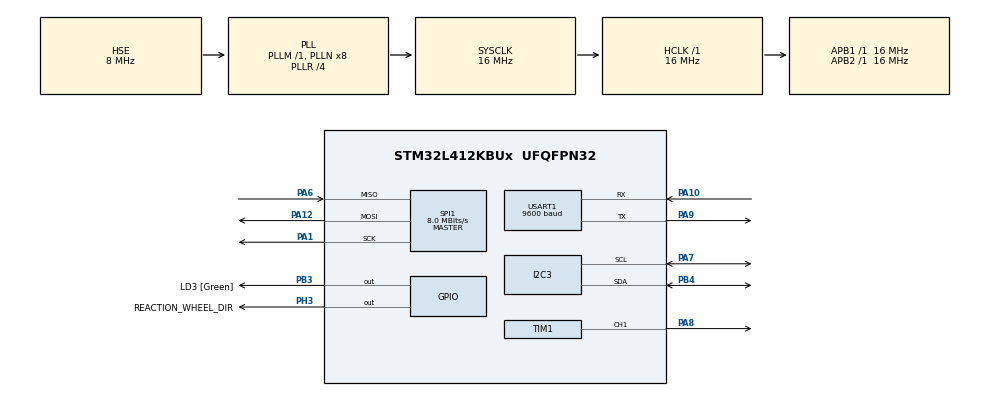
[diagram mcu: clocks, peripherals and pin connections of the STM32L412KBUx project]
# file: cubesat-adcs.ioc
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FREERTOS.Tasks01=defaultTask,24,128,StartDefaultTask,Default,NULL,Dynamic,NULL,NULL
FREERTOS.configENABLE_FPU=1
FREERTOS.configTOTAL_HEAP_SIZE=10000
FREERTOS.configUSE_NEWLIB_REENTRANT=1
I2C3.Timing=0x00303D5B
Mcu.Family=STM32L4
Mcu.Name=STM32L412KBUx
Mcu.Package=UFQFPN32
NVIC.I2C3_ER_IRQn=true\:5\:0\:false\:false\:true\:true\:true\:true
NVIC.I2C3_EV_IRQn=true\:5\:0\:false\:false\:true\:true\:true\:true
NVIC.PriorityGroup=NVIC_PRIORITYGROUP_4
NVIC.TIM1_UP_TIM16_IRQn=true\:5\:0\:false\:false\:true\:false\:false\:true
NVIC.TimeBase=TIM1_UP_TIM16_IRQn
NVIC.TimeBaseIP=TIM16
NVIC.USART1_IRQn=true\:5\:0\:false\:false\:true\:true\:true\:true
PA0-CK_IN.Mode=HSE-External-Clock-Source-for-LittleOrca
PA0-CK_IN.Signal=RCC_CK_IN
PA1.Mode=Full_Duplex_Master
PA1.Signal=SPI1_SCK
PA10.Mode=Asynchronous
PA10.Signal=USART1_RX
PA12.Mode=Full_Duplex_Master
PA12.Signal=SPI1_MOSI
PA13\ (JTMS/SWDIO).GPIO_Label=SWDIO
PA13\ (JTMS/SWDIO).Mode=Serial_Wire
PA13\ (JTMS/SWDIO).Signal=SYS_JTMS-SWDIO
PA14\ (JTCK/SWCLK).GPIO_Label=SWCLK
PA14\ (JTCK/SWCLK).Mode=Serial_Wire
PA14\ (JTCK/SWCLK).Signal=SYS_JTCK-SWCLK
PA6.Mode=Full_Duplex_Master
PA6.Signal=SPI1_MISO
PA7.Mode=I2C
PA7.Signal=I2C3_SCL
PA8.Signal=S_TIM1_CH1
PA9.Mode=Asynchronous
PA9.Signal=USART1_TX
PB3\ (JTDO/TRACESWO).GPIO_Label=LD3 [Green]
PB3\ (JTDO/TRACESWO).Signal=GPIO_Output
PB4\ (NJTRST).Mode=I2C
PB4\ (NJTRST).Signal=I2C3_SDA
PC14-OSC32_IN\ (PC14).Mode=LSE-External-Oscillator
PC14-OSC32_IN\ (PC14).Signal=RCC_OSC32_IN
PC15-OSC32_OUT\ (PC15).Mode=LSE-External-Oscillator
PC15-OSC32_OUT\ (PC15).Signal=RCC_OSC32_OUT
PH3-BOOT0\ (BOOT0).GPIO_Label=REACTION_WHEEL_DIR
PH3-BOOT0\ (BOOT0).GPIO_Speed=GPIO_SPEED_FREQ_MEDIUM
PH3-BOOT0\ (BOOT0).Signal=GPIO_Output
ProjectManager.HeapSize=0x200
ProjectManager.StackSize=0x400
ProjectManager.TargetToolchain=STM32CubeIDE
RCC.ADCFreq_Value=16000000
RCC.AHBFreq_Value=16000000
RCC.APB1Freq_Value=16000000
RCC.APB1TimFreq_Value=16000000
RCC.APB2Freq_Value=16000000
RCC.APB2TimFreq_Value=16000000
RCC.CortexFreq_Value=16000000
RCC.FLatency=FLASH_LATENCY_0
RCC.HCLKFreq_Value=16000000
RCC.HSE_VALUE=8000000
RCC.HSI48_VALUE=48000000
RCC.HSICalibrationValue=16
RCC.HSI_VALUE=16000000
RCC.MSIClockRange=RCC_MSIRANGE_10
RCC.MSI_VALUE=32000000
RCC.PLLR=RCC_PLLR_DIV4
RCC.PLLSourceVirtual=RCC_PLLSOURCE_HSE
RCC.SYSCLKFreq_VALUE=16000000
RCC.SYSCLKSource=RCC_SYSCLKSOURCE_PLLCLK
RCC.USART1CLockSelection=RCC_USART1CLKSOURCE_SYSCLK
RCC.USART2CLockSelection=RCC_USART2CLKSOURCE_HSI
RCC.USBFreq_Value=32000000
RCC.VCOOutputFreq_Value=64000000
SH.S_TIM1_CH1.0=TIM1_CH1,PWM Generation1 CH1
SPI1.CalculateBaudRate=8.0 MBits/s
SPI1.Direction=SPI_DIRECTION_2LINES
SPI1.Mode=SPI_MODE_MASTER
SPI1.VirtualType=VM_MASTER
TIM1.AutoReloadPreload=TIM_AUTORELOAD_PRELOAD_ENABLE
TIM1.Channel-PWM\ Generation1\ CH1=TIM_CHANNEL_1
USART1.BaudRate=9600
USART1.VirtualMode-Asynchronous=VM_ASYNC
VP_FREERTOS_VS_CMSIS_V2.Mode=CMSIS_V2
VP_SYS_VS_tim16.Mode=TIM16
board=NUCLEO-L412KB

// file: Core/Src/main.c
/* USER CODE BEGIN Header */
/**
 ******************************************************************************
 * @file           : main.c
 * @brief          : Main program body
 ******************************************************************************
 * @attention
 *
 * <h2><center>&copy; Copyright (c) 2021 STMicroelectronics.
 * All rights reserved.</center></h2>
 *
 * This software component is licensed by ST under BSD 3-Clause license,
 * the "License"; You may not use this file except in compliance with the
 * License. You may obtain a copy of the License at:
 *                        opensource.org/licenses/BSD-3-Clause
 *
 ******************************************************************************
 */
/* USER CODE END Header */
#include "main.h"
#include "cmsis_os.h"
#include "i2c.h"
#include "spi.h"
#include "tim.h"
#include "usart.h"
#include "gpio.h"

void SystemClock_Config(void);
void MX_FREERTOS_Init(void);

int main(void)
{

  /* MCU Configuration--------------------------------------------------------*/

  /* Reset of all peripherals, Initializes the Flash interface and the Systick. */
  HAL_Init();

  /* Configure the system clock */
  SystemClock_Config();

  /* Initialize all configured peripherals */
  MX_GPIO_Init();
  MX_SPI1_Init();
  MX_TIM1_Init();
  MX_USART1_UART_Init();
  MX_I2C3_Init();

  /* Init scheduler */
  osKernelInitialize();  /* Call init function for freertos objects (in freertos.c) */
  MX_FREERTOS_Init();
  /* Start scheduler */
  osKernelStart();

  /* We should never get here as control is now taken by the scheduler */
  /* Infinite loop */
    while (1) {

    }
}

void SystemClock_Config(void)
{
  RCC_OscInitTypeDef RCC_OscInitStruct = {0};
  RCC_ClkInitTypeDef RCC_ClkInitStruct = {0};

  /** Configure the main internal regulator output voltage
  */
  if (HAL_PWREx_ControlVoltageScaling(PWR_REGULATOR_VOLTAGE_SCALE1) != HAL_OK)
  {
    Error_Handler();
  }
  /** Initializes the RCC Oscillators according to the specified parameters
  * in the RCC_OscInitTypeDef structure.
  */
  RCC_OscInitStruct.OscillatorType = RCC_OSCILLATORTYPE_HSE;
  RCC_OscInitStruct.HSEState = RCC_HSE_BYPASS;
  RCC_OscInitStruct.PLL.PLLState = RCC_PLL_ON;
  RCC_OscInitStruct.PLL.PLLSource = RCC_PLLSOURCE_HSE;
  RCC_OscInitStruct.PLL.PLLM = 1;
  RCC_OscInitStruct.PLL.PLLN = 8;
  RCC_OscInitStruct.PLL.PLLQ = RCC_PLLQ_DIV2;
  RCC_OscInitStruct.PLL.PLLR = RCC_PLLR_DIV4;
  if (HAL_RCC_OscConfig(&RCC_OscInitStruct) != HAL_OK)
  {
    Error_Handler();
  }
  /** Initializes the CPU, AHB and APB buses clocks
  */
  RCC_ClkInitStruct.ClockType = RCC_CLOCKTYPE_HCLK|RCC_CLOCKTYPE_SYSCLK
                              |RCC_CLOCKTYPE_PCLK1|RCC_CLOCKTYPE_PCLK2;
  RCC_ClkInitStruct.SYSCLKSource = RCC_SYSCLKSOURCE_PLLCLK;
  RCC_ClkInitStruct.AHBCLKDivider = RCC_SYSCLK_DIV1;
  RCC_ClkInitStruct.APB1CLKDivider = RCC_HCLK_DIV1;
  RCC_ClkInitStruct.APB2CLKDivider = RCC_HCLK_DIV1;

  if (HAL_RCC_ClockConfig(&RCC_ClkInitStruct, FLASH_LATENCY_0) != HAL_OK)
  {
    Error_Handler();
  }
}

/* USER CODE BEGIN 4 */
void SignalFaultCondition(void)
{
	HAL_GPIO_WritePin(LD3_GPIO_Port, LD3_Pin, GPIO_PIN_SET);
}

/* USER CODE END 4 */

void HAL_TIM_PeriodElapsedCallback(TIM_HandleTypeDef *htim)
{
  if (htim->Instance == TIM16) {
    HAL_IncTick();
  }
}

void Error_Handler(void)
{
    __disable_irq();
    while (1) {
    }
}

/************************ (C) COPYRIGHT STMicroelectronics *****END OF FILE****/

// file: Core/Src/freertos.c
/* USER CODE BEGIN Header */
/**
  ******************************************************************************
  * File Name          : freertos.c
  * Description        : Code for freertos applications
  ******************************************************************************
  * @attention
  *
  * <h2><center>&copy; Copyright (c) 2021 STMicroelectronics.
  * All rights reserved.</center></h2>
  *
  * This software component is licensed by ST under Ultimate Liberty license
  * SLA0044, the "License"; You may not use this file except in compliance with
  * the License. You may obtain a copy of the License at:
  *                             www.st.com/SLA0044
  *
  ******************************************************************************
  */
/* USER CODE END Header */

#include "FreeRTOS.h"
#include "task.h"
#include "main.h"
#include "cmsis_os.h"

/* USER CODE BEGIN Includes */
#include "adcs_tasks.hpp"

/* USER CODE END Includes */

/* Definitions for defaultTask */
osThreadId_t defaultTaskHandle;
const osThreadAttr_t defaultTask_attributes = {
  .name = "defaultTask",
  .stack_size = 128 * 4,
  .priority = (osPriority_t) osPriorityNormal,
};

void StartDefaultTask(void *argument);

void MX_FREERTOS_Init(void); /* (MISRA C 2004 rule 8.1) */

void MX_FREERTOS_Init(void) {

  /* Create the thread(s) */
  /* creation of defaultTask */
  defaultTaskHandle = osThreadNew(StartDefaultTask, NULL, &defaultTask_attributes);

  /* USER CODE BEGIN RTOS_THREADS */
    /* add threads, ... */
    initAdcsThreads();

  /* USER CODE END RTOS_THREADS */

}

void StartDefaultTask(void *argument)
{
    for (;;) {
    }
}

/************************ (C) COPYRIGHT STMicroelectronics *****END OF FILE****/
